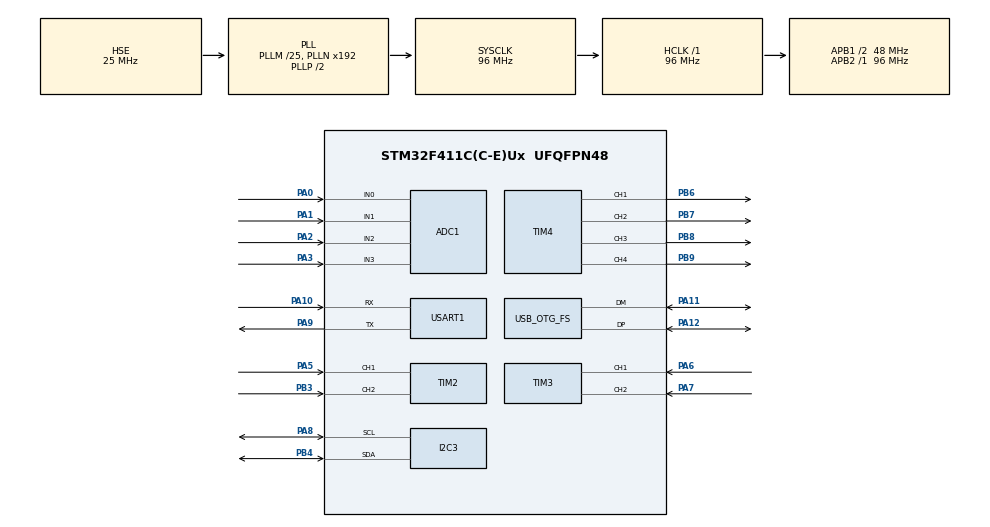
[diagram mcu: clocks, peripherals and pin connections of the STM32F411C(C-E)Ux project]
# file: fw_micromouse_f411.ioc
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ADC1.Channel-0\#ChannelRegularConversion=ADC_CHANNEL_0
ADC1.NbrOfConversionFlag=1
ADC1.Rank-0\#ChannelRegularConversion=1
ADC1.SamplingTime-0\#ChannelRegularConversion=ADC_SAMPLETIME_3CYCLES
ADC1.master=1
Mcu.Family=STM32F4
Mcu.Name=STM32F411C(C-E)Ux
Mcu.Package=UFQFPN48
NVIC.OTG_FS_IRQn=true\:0\:0\:false\:false\:true\:false\:true\:true
NVIC.PriorityGroup=NVIC_PRIORITYGROUP_4
PA0-WKUP.Signal=ADCx_IN0
PA1.Signal=ADCx_IN1
PA10.Mode=Asynchronous
PA10.Signal=USART1_RX
PA11.Mode=Device_Only
PA11.Signal=USB_OTG_FS_DM
PA12.Mode=Device_Only
PA12.Signal=USB_OTG_FS_DP
PA2.Signal=ADCx_IN2
PA3.Signal=ADCx_IN3
PA5.Signal=S_TIM2_CH1_ETR
PA6.Signal=S_TIM3_CH1
PA7.Signal=S_TIM3_CH2
PA8.Mode=I2C
PA8.Signal=I2C3_SCL
PA9.Mode=Asynchronous
PA9.Signal=USART1_TX
PB3.Signal=S_TIM2_CH2
PB4.Mode=I2C
PB4.Signal=I2C3_SDA
PB6.Signal=S_TIM4_CH1
PB7.Signal=S_TIM4_CH2
PB8.Signal=S_TIM4_CH3
PB9.Signal=S_TIM4_CH4
PH0\ -\ OSC_IN.Mode=HSE-External-Oscillator
PH0\ -\ OSC_IN.Signal=RCC_OSC_IN
PH1\ -\ OSC_OUT.Mode=HSE-External-Oscillator
PH1\ -\ OSC_OUT.Signal=RCC_OSC_OUT
ProjectManager.HeapSize=0x200
ProjectManager.StackSize=0x400
ProjectManager.TargetToolchain=STM32CubeIDE
RCC.48MHZClocksFreq_Value=48000000
RCC.AHBFreq_Value=96000000
RCC.APB1CLKDivider=RCC_HCLK_DIV2
RCC.APB1Freq_Value=48000000
RCC.APB1TimFreq_Value=96000000
RCC.APB2Freq_Value=96000000
RCC.APB2TimFreq_Value=96000000
RCC.CortexFreq_Value=96000000
RCC.HCLKFreq_Value=96000000
RCC.HSE_VALUE=25000000
RCC.HSI_VALUE=16000000
RCC.LSE_VALUE=32768
RCC.PLLM=25
RCC.SYSCLKFreq_VALUE=96000000
RCC.SYSCLKSource=RCC_SYSCLKSOURCE_PLLCLK
RCC.VCOOutputFreq_Value=192000000
SH.ADCx_IN0.0=ADC1_IN0,IN0
SH.ADCx_IN1.0=ADC1_IN1,IN1
SH.ADCx_IN2.0=ADC1_IN2,IN2
SH.ADCx_IN3.0=ADC1_IN3,IN3
SH.S_TIM2_CH1_ETR.0=TIM2_CH1,Encoder_Interface
SH.S_TIM2_CH2.0=TIM2_CH2,Encoder_Interface
SH.S_TIM3_CH1.0=TIM3_CH1,Encoder_Interface
SH.S_TIM3_CH2.0=TIM3_CH2,Encoder_Interface
SH.S_TIM4_CH1.0=TIM4_CH1,PWM Generation1 CH1
SH.S_TIM4_CH2.0=TIM4_CH2,PWM Generation2 CH2
SH.S_TIM4_CH3.0=TIM4_CH3,PWM Generation3 CH3
SH.S_TIM4_CH4.0=TIM4_CH4,PWM Generation4 CH4
TIM4.Channel-PWM\ Generation1\ CH1=TIM_CHANNEL_1
TIM4.Channel-PWM\ Generation2\ CH2=TIM_CHANNEL_2
TIM4.Channel-PWM\ Generation3\ CH3=TIM_CHANNEL_3
TIM4.Channel-PWM\ Generation4\ CH4=TIM_CHANNEL_4
USART1.VirtualMode=VM_ASYNC
USB_DEVICE.CLASS_NAME_FS=CDC
USB_DEVICE.VirtualMode=Cdc
USB_DEVICE.VirtualModeFS=Cdc_FS
USB_OTG_FS.VirtualMode=Device_Only
VP_USB_DEVICE_VS_USB_DEVICE_CDC_FS.Mode=CDC_FS
board=custom

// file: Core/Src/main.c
/* USER CODE BEGIN Header */
/**
  ******************************************************************************
  * @file           : main.c
  * @brief          : Main program body
  ******************************************************************************
  * @attention
  *
  * Copyright (c) 2026 STMicroelectronics.
  * All rights reserved.
  *
  * This software is licensed under terms that can be found in the LICENSE file
  * in the root directory of this software component.
  * If no LICENSE file comes with this software, it is provided AS-IS.
  *
  ******************************************************************************
  */
/* USER CODE END Header */
#include "main.h"
#include "usb_device.h"

/* USER CODE BEGIN Includes */
#include "app_main.h"
/* USER CODE END Includes */

ADC_HandleTypeDef hadc1;

I2C_HandleTypeDef hi2c3;

TIM_HandleTypeDef htim2;
TIM_HandleTypeDef htim3;
TIM_HandleTypeDef htim4;

UART_HandleTypeDef huart1;

void SystemClock_Config(void);
static void MX_GPIO_Init(void);
static void MX_ADC1_Init(void);
static void MX_I2C3_Init(void);
static void MX_TIM2_Init(void);
static void MX_TIM3_Init(void);
static void MX_TIM4_Init(void);
static void MX_USART1_UART_Init(void);

int main(void)
{

  /* MCU Configuration--------------------------------------------------------*/

  /* Reset of all peripherals, Initializes the Flash interface and the Systick. */
  HAL_Init();

  /* Configure the system clock */
  SystemClock_Config();

  /* Initialize all configured peripherals */
  MX_GPIO_Init();
  MX_ADC1_Init();
  MX_I2C3_Init();
  MX_TIM2_Init();
  MX_TIM3_Init();
  MX_TIM4_Init();
  MX_USART1_UART_Init();
  MX_USB_DEVICE_Init();
  /* USER CODE BEGIN 2 */
  app_init();
  /* USER CODE END 2 */

  /* Infinite loop */
  while (1)
  {

    /* USER CODE BEGIN 3 */
    app_loop();
  }
  /* USER CODE END 3 */
}

void SystemClock_Config(void)
{
  RCC_OscInitTypeDef RCC_OscInitStruct = {0};
  RCC_ClkInitTypeDef RCC_ClkInitStruct = {0};

  /** Configure the main internal regulator output voltage
  */
  __HAL_RCC_PWR_CLK_ENABLE();
  __HAL_PWR_VOLTAGESCALING_CONFIG(PWR_REGULATOR_VOLTAGE_SCALE1);

  /** Initializes the RCC Oscillators according to the specified parameters
  * in the RCC_OscInitTypeDef structure.
  */
  RCC_OscInitStruct.OscillatorType = RCC_OSCILLATORTYPE_HSE;
  RCC_OscInitStruct.HSEState = RCC_HSE_ON;
  RCC_OscInitStruct.PLL.PLLState = RCC_PLL_ON;
  RCC_OscInitStruct.PLL.PLLSource = RCC_PLLSOURCE_HSE;
  RCC_OscInitStruct.PLL.PLLM = 25;
  RCC_OscInitStruct.PLL.PLLN = 192;
  RCC_OscInitStruct.PLL.PLLP = RCC_PLLP_DIV2;
  RCC_OscInitStruct.PLL.PLLQ = 4;
  if (HAL_RCC_OscConfig(&RCC_OscInitStruct) != HAL_OK)
  {
    Error_Handler();
  }

  /** Initializes the CPU, AHB and APB buses clocks
  */
  RCC_ClkInitStruct.ClockType = RCC_CLOCKTYPE_HCLK|RCC_CLOCKTYPE_SYSCLK
                              |RCC_CLOCKTYPE_PCLK1|RCC_CLOCKTYPE_PCLK2;
  RCC_ClkInitStruct.SYSCLKSource = RCC_SYSCLKSOURCE_PLLCLK;
  RCC_ClkInitStruct.AHBCLKDivider = RCC_SYSCLK_DIV1;
  RCC_ClkInitStruct.APB1CLKDivider = RCC_HCLK_DIV2;
  RCC_ClkInitStruct.APB2CLKDivider = RCC_HCLK_DIV1;

  if (HAL_RCC_ClockConfig(&RCC_ClkInitStruct, FLASH_LATENCY_3) != HAL_OK)
  {
    Error_Handler();
  }
}

static void MX_ADC1_Init(void)
{

  ADC_ChannelConfTypeDef sConfig = {0};

  /** Configure the global features of the ADC (Clock, Resolution, Data Alignment and number of conversion)
  */
  hadc1.Instance = ADC1;
  hadc1.Init.ClockPrescaler = ADC_CLOCK_SYNC_PCLK_DIV4;
  hadc1.Init.Resolution = ADC_RESOLUTION_12B;
  hadc1.Init.ScanConvMode = DISABLE;
  hadc1.Init.ContinuousConvMode = DISABLE;
  hadc1.Init.DiscontinuousConvMode = DISABLE;
  hadc1.Init.ExternalTrigConvEdge = ADC_EXTERNALTRIGCONVEDGE_NONE;
  hadc1.Init.ExternalTrigConv = ADC_SOFTWARE_START;
  hadc1.Init.DataAlign = ADC_DATAALIGN_RIGHT;
  hadc1.Init.NbrOfConversion = 1;
  hadc1.Init.DMAContinuousRequests = DISABLE;
  hadc1.Init.EOCSelection = ADC_EOC_SINGLE_CONV;
  if (HAL_ADC_Init(&hadc1) != HAL_OK)
  {
    Error_Handler();
  }

  /** Configure for the selected ADC regular channel its corresponding rank in the sequencer and its sample time.
  */
  sConfig.Channel = ADC_CHANNEL_0;
  sConfig.Rank = 1;
  sConfig.SamplingTime = ADC_SAMPLETIME_3CYCLES;
  if (HAL_ADC_ConfigChannel(&hadc1, &sConfig) != HAL_OK)
  {
    Error_Handler();
  }

}

static void MX_I2C3_Init(void)
{

  hi2c3.Instance = I2C3;
  hi2c3.Init.ClockSpeed = 100000;
  hi2c3.Init.DutyCycle = I2C_DUTYCYCLE_2;
  hi2c3.Init.OwnAddress1 = 0;
  hi2c3.Init.AddressingMode = I2C_ADDRESSINGMODE_7BIT;
  hi2c3.Init.DualAddressMode = I2C_DUALADDRESS_DISABLE;
  hi2c3.Init.OwnAddress2 = 0;
  hi2c3.Init.GeneralCallMode = I2C_GENERALCALL_DISABLE;
  hi2c3.Init.NoStretchMode = I2C_NOSTRETCH_DISABLE;
  if (HAL_I2C_Init(&hi2c3) != HAL_OK)
  {
    Error_Handler();
  }

}

static void MX_TIM2_Init(void)
{

  TIM_Encoder_InitTypeDef sConfig = {0};
  TIM_MasterConfigTypeDef sMasterConfig = {0};

  htim2.Instance = TIM2;
  htim2.Init.Prescaler = 0;
  htim2.Init.CounterMode = TIM_COUNTERMODE_UP;
  htim2.Init.Period = 4294967295;
  htim2.Init.ClockDivision = TIM_CLOCKDIVISION_DIV1;
  htim2.Init.AutoReloadPreload = TIM_AUTORELOAD_PRELOAD_DISABLE;
  sConfig.EncoderMode = TIM_ENCODERMODE_TI1;
  sConfig.IC1Polarity = TIM_ICPOLARITY_RISING;
  sConfig.IC1Selection = TIM_ICSELECTION_DIRECTTI;
  sConfig.IC1Prescaler = TIM_ICPSC_DIV1;
  sConfig.IC1Filter = 0;
  sConfig.IC2Polarity = TIM_ICPOLARITY_RISING;
  sConfig.IC2Selection = TIM_ICSELECTION_DIRECTTI;
  sConfig.IC2Prescaler = TIM_ICPSC_DIV1;
  sConfig.IC2Filter = 0;
  if (HAL_TIM_Encoder_Init(&htim2, &sConfig) != HAL_OK)
  {
    Error_Handler();
  }
  sMasterConfig.MasterOutputTrigger = TIM_TRGO_RESET;
  sMasterConfig.MasterSlaveMode = TIM_MASTERSLAVEMODE_DISABLE;
  if (HAL_TIMEx_MasterConfigSynchronization(&htim2, &sMasterConfig) != HAL_OK)
  {
    Error_Handler();
  }

}

static void MX_TIM3_Init(void)
{

  TIM_Encoder_InitTypeDef sConfig = {0};
  TIM_MasterConfigTypeDef sMasterConfig = {0};

  htim3.Instance = TIM3;
  htim3.Init.Prescaler = 0;
  htim3.Init.CounterMode = TIM_COUNTERMODE_UP;
  htim3.Init.Period = 65535;
  htim3.Init.ClockDivision = TIM_CLOCKDIVISION_DIV1;
  htim3.Init.AutoReloadPreload = TIM_AUTORELOAD_PRELOAD_DISABLE;
  sConfig.EncoderMode = TIM_ENCODERMODE_TI1;
  sConfig.IC1Polarity = TIM_ICPOLARITY_RISING;
  sConfig.IC1Selection = TIM_ICSELECTION_DIRECTTI;
  sConfig.IC1Prescaler = TIM_ICPSC_DIV1;
  sConfig.IC1Filter = 0;
  sConfig.IC2Polarity = TIM_ICPOLARITY_RISING;
  sConfig.IC2Selection = TIM_ICSELECTION_DIRECTTI;
  sConfig.IC2Prescaler = TIM_ICPSC_DIV1;
  sConfig.IC2Filter = 0;
  if (HAL_TIM_Encoder_Init(&htim3, &sConfig) != HAL_OK)
  {
    Error_Handler();
  }
  sMasterConfig.MasterOutputTrigger = TIM_TRGO_RESET;
  sMasterConfig.MasterSlaveMode = TIM_MASTERSLAVEMODE_DISABLE;
  if (HAL_TIMEx_MasterConfigSynchronization(&htim3, &sMasterConfig) != HAL_OK)
  {
    Error_Handler();
  }

}

static void MX_TIM4_Init(void)
{

  TIM_MasterConfigTypeDef sMasterConfig = {0};
  TIM_OC_InitTypeDef sConfigOC = {0};

  htim4.Instance = TIM4;
  htim4.Init.Prescaler = 0;
  htim4.Init.CounterMode = TIM_COUNTERMODE_UP;
  htim4.Init.Period = 65535;
  htim4.Init.ClockDivision = TIM_CLOCKDIVISION_DIV1;
  htim4.Init.AutoReloadPreload = TIM_AUTORELOAD_PRELOAD_DISABLE;
  if (HAL_TIM_PWM_Init(&htim4) != HAL_OK)
  {
    Error_Handler();
  }
  sMasterConfig.MasterOutputTrigger = TIM_TRGO_RESET;
  sMasterConfig.MasterSlaveMode = TIM_MASTERSLAVEMODE_DISABLE;
  if (HAL_TIMEx_MasterConfigSynchronization(&htim4, &sMasterConfig) != HAL_OK)
  {
    Error_Handler();
  }
  sConfigOC.OCMode = TIM_OCMODE_PWM1;
  sConfigOC.Pulse = 0;
  sConfigOC.OCPolarity = TIM_OCPOLARITY_HIGH;
  sConfigOC.OCFastMode = TIM_OCFAST_DISABLE;
  if (HAL_TIM_PWM_ConfigChannel(&htim4, &sConfigOC, TIM_CHANNEL_1) != HAL_OK)
  {
    Error_Handler();
  }
  if (HAL_TIM_PWM_ConfigChannel(&htim4, &sConfigOC, TIM_CHANNEL_2) != HAL_OK)
  {
    Error_Handler();
  }
  if (HAL_TIM_PWM_ConfigChannel(&htim4, &sConfigOC, TIM_CHANNEL_3) != HAL_OK)
  {
    Error_Handler();
  }
  if (HAL_TIM_PWM_ConfigChannel(&htim4, &sConfigOC, TIM_CHANNEL_4) != HAL_OK)
  {
    Error_Handler();
  }
  HAL_TIM_MspPostInit(&htim4);

}

static void MX_USART1_UART_Init(void)
{

  huart1.Instance = USART1;
  huart1.Init.BaudRate = 115200;
  huart1.Init.WordLength = UART_WORDLENGTH_8B;
  huart1.Init.StopBits = UART_STOPBITS_1;
  huart1.Init.Parity = UART_PARITY_NONE;
  huart1.Init.Mode = UART_MODE_TX_RX;
  huart1.Init.HwFlowCtl = UART_HWCONTROL_NONE;
  huart1.Init.OverSampling = UART_OVERSAMPLING_16;
  if (HAL_UART_Init(&huart1) != HAL_OK)
  {
    Error_Handler();
  }

}

static void MX_GPIO_Init(void)
{

  /* GPIO Ports Clock Enable */
  __HAL_RCC_GPIOH_CLK_ENABLE();
  __HAL_RCC_GPIOA_CLK_ENABLE();
  __HAL_RCC_GPIOB_CLK_ENABLE();

}

void Error_Handler(void)
{
  /* USER CODE BEGIN Error_Handler_Debug */
  /* User can add his own implementation to report the HAL error return state */
  app_emergency_stop();
  __disable_irq();
  while (1)
  {
  }
  /* USER CODE END Error_Handler_Debug */
}
